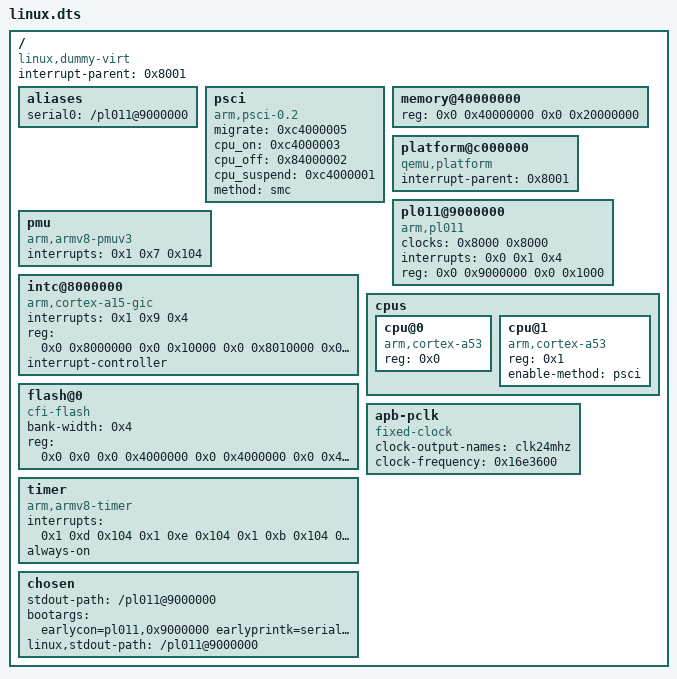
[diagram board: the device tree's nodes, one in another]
// Copyright Linux
// SPDX-License-Identifier: GPL-2.0-or-later

/dts-v1/;

/ {
	interrupt-parent = <0x8001>;
	#size-cells = <0x2>;
	#address-cells = <0x2>;
	compatible = "linux,dummy-virt";

    aliases {
		serial0 = "/pl011@9000000";
    };

    psci {
		migrate = <0xc4000005>;
		cpu_on = <0xc4000003>;
		cpu_off = <0x84000002>;
		cpu_suspend = <0xc4000001>;
		method = "smc";
		compatible = "arm,psci-0.2", "arm,psci";
	};

    memory@40000000 {
		reg = <0x0 0x40000000 0x0 0x20000000>;
		device_type = "memory";
	};

	platform@c000000 {
		interrupt-parent = <0x8001>;
		ranges = <0x0 0x0 0xc000000 0x2000000>;
		#address-cells = <0x1>;
		#size-cells = <0x1>;
		compatible = "qemu,platform", "simple-bus";
	};

	pl011@9000000 {
		clock-names = "uartclk", "apb_pclk";
		clocks = <0x8000 0x8000>;
		interrupts = <0x0 0x1 0x4>;
		reg = <0x0 0x9000000 0x0 0x1000>;
		compatible = "arm,pl011", "arm,primecell";
	};

	pmu {
		interrupts = <0x1 0x7 0x104>;
		compatible = "arm,armv8-pmuv3";
	};

	intc@8000000 {
		phandle = <0x8001>;
		interrupts = <0x1 0x9 0x4>;
		reg = <0x0 0x8000000 0x0 0x10000 0x0 0x8010000 0x0 0x10000 0x0 0x8030000 0x0 0x10000 0x0 0x8040000 0x0 0x10000>;
		compatible = "arm,cortex-a15-gic";
		ranges;
		#size-cells = <0x2>;
		#address-cells = <0x2>;
		interrupt-controller;
		#interrupt-cells = <0x3>;
	};

	flash@0 {
		bank-width = <0x4>;
		reg = <0x0 0x0 0x0 0x4000000 0x0 0x4000000 0x0 0x4000000>;
		compatible = "cfi-flash";
	};

	cpus {
		#size-cells = <0x0>;
		#address-cells = <0x1>;

		cpu@0 {
			reg = <0x0>;
			compatible = "arm,cortex-a53";
			device_type = "cpu";
		};

        cpu@1 {
			reg = <0x1>;
			enable-method = "psci";
			compatible = "arm,cortex-a53";
			device_type = "cpu";
		};
	};

	timer {
		interrupts = <0x1 0xd 0x104 0x1 0xe 0x104 0x1 0xb 0x104 0x1 0xa 0x104>;
		always-on;
		compatible = "arm,armv8-timer", "arm,armv7-timer";
	};

	apb-pclk {
		phandle = <0x8000>;
		clock-output-names = "clk24mhz";
		clock-frequency = <0x16e3600>;
		#clock-cells = <0x0>;
		compatible = "fixed-clock";
	};

	chosen {
		stdout-path = "/pl011@9000000";
		bootargs = "earlycon=pl011,0x9000000 earlyprintk=serial debug loglevel=8";
		linux,stdout-path = "/pl011@9000000";
    };
};
